# AT32UC3A464S device description
Architecture: AVR32_UC3; Family: AVR UC3
Registers are 32-bit, read-write, reset 0x0 unless marked. A register's access mark holds for its fields unless they carry their own. Offsets are from the block's base; [hi:lo] are bit positions; {n}, {i} and the like mark numbered series.

## AES — Advanced Encryption Standard
Instances: AES 0xfffd0000
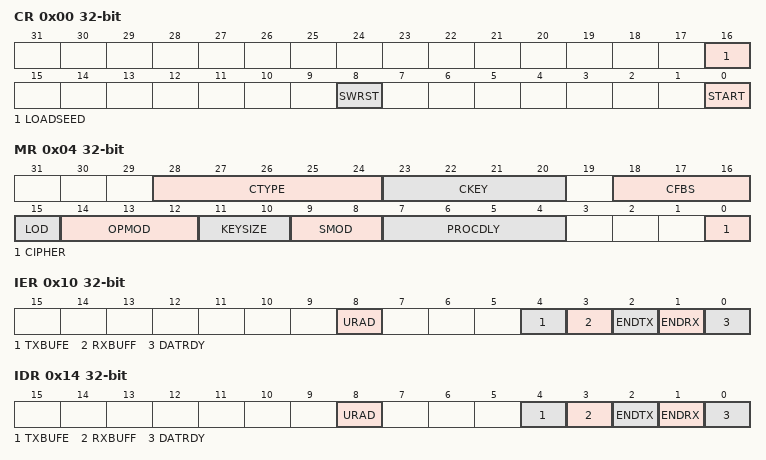
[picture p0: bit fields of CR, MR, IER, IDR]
0x00 CR wo reset not defined — Control Register
  [16] LOADSEED — Random Number Generator Seed Loading
  [8] SWRST — Software Reset
  [0] START — Start Processing
0x04 MR — Mode Register
  [28:24] CTYPE — Countermeasure Type
  [23:20] CKEY — Countermeasure Key
  [18:16] CFBS — Chiper Feedback Data Size
  [15] LOD — Last Output Data Mode
  [14:12] OPMOD — Operation Mode
  [11:10] KEYSIZE
  [9:8] SMOD — Start Mode
  [7:4] PROCDLY — Processing Delay
  [0] CIPHER — Processing Mode
0x10 IER wo reset not defined — Interrupt Enable Register
  [8] URAD — Unspecified Register Access Detection Interrupt Enable
  [4] TXBUFE — Receive Buffer Empty Interrupt Enable
  [3] RXBUFF — Receive Buffer Full Interrupt Enable
  [2] ENDTX — End of Transmit Buffer Interrupt Enable
  [1] ENDRX — End of Receive Buffer Interrupt Enable
  [0] DATRDY — Data Ready Interrupt Enable
0x14 IDR wo reset not defined — Interrupt Disable Register
  [8] URAD — Unspecified Register Access Detection Interrupt Disable
  [4] TXBUFE — Receive Buffer Empty Interrupt Disable
  [3] RXBUFF — Receive Buffer Full Interrupt Disable
  [2] ENDTX — End of Transmit Buffer Interrupt Disable
  [1] ENDRX — End of Receive Buffer Interrupt Disable
  [0] DATRDY — Data Ready Interrupt Disable
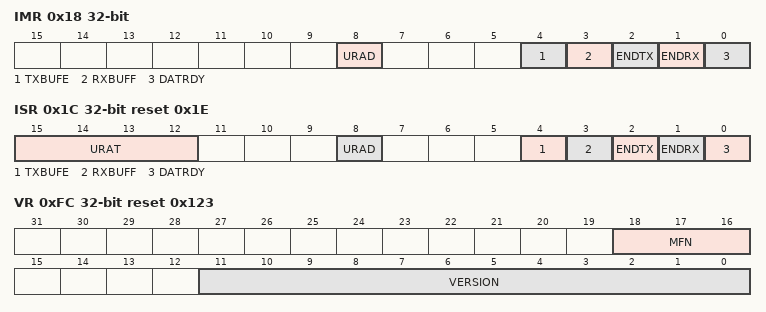
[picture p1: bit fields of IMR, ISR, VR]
0x18 IMR ro — Interrupt Mask Register
  [8] URAD — Unspecified Register Access Detection Interrupt Mask
  [4] TXBUFE — Receive Buffer Empty Interrupt Mask
  [3] RXBUFF — Receive Buffer Full Interrupt Mask
  [2] ENDTX — End of Transmit Buffer Interrupt Mask
  [1] ENDRX — End of Receive Buffer Interrupt Mask
  [0] DATRDY — Data Ready Interrupt Mask
0x1C ISR ro reset 0x1E — Interrupt Status Register
  [15:12] URAT — Unspecified Register Access Type
  [8] URAD — Unspecified Register Access Detection Status
  [4] TXBUFE — TX Buffer Empty
  [3] RXBUFF — RX Buffer Full
  [2] ENDTX — End of TX Buffer
  [1] ENDRX — End of RX Buffer
  [0] DATRDY — Data Ready
{0x1C+4i} KEYW{i}R wo reset not defined (i=1..8) — Key Word {i} Register
  [31:0] KEYWxR — AES Key Word x Register
0x40 IDATA1R wo reset not defined — Input Data 1 Register
  [31:0] IDATAx — Input Data Word x
0x44 IDATA2R wo reset not defined — Input Data 2 Register
  [31:0] IDATAx — Input Data Word x
0x48 IDATA3R wo reset not defined — Input Data 3 Register
  [31:0] IDATAx
0x4C IDATA4R wo reset not defined — Input Data 4 Register
  [31:0] IDATAx
0x50 ODATA1R ro — Output Data 1 Register
  [31:0] ODATAxR — AES Output Data x Register
0x54 ODATA2R ro reset 0xC01F0000 — Output Data 2 Register
  [31:0] ODATAxR — AES Output Data x Register
0x58 ODATA3R ro — Output Data 3 Register
  [31:0] ODATAxR — AES Output Data x Register
0x5C ODATA4R ro — Output Data 4 Register
  [31:0] ODATAxR — AES Output Data x Register
{0x5C+4i} IV{i}R wo reset not defined (i=1..3) — Initialization Vector {i} Register
  [31:0] IVxR — AES Initialization Vector x Register
0x6C IV4E wo reset not defined — Initialization Vector 4 Register
  [31:0] IVxR — AES Initialization Vector x Register
0xFC VR ro reset 0x123 — AES version
  [18:16] MFN — Metal fix number
  [11:0] VERSION — AES version

## BUSMON — Bus Monitor module
Instances: BUSMON 0xfffe2800
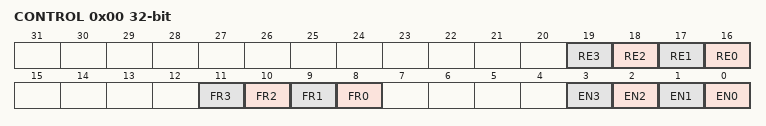
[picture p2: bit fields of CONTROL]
0x00 CONTROL
  [n+16] RE{n} (n=0..3), [n+8] FR{n} (n=0..3), [n] EN{n} (n=0..3)
{0x10+0x10*i} DATA{i} ro (i=0..3) — Data Cycles Channel {i}
{0x14+0x10*i} STALL{i} ro (i=0..3) — Stall Cycles Channel {i}
{0x18+0x10*i} LAT{i} ro (i=0..3) — Max Latency Cycles Channel {i}

## ABDAC — Audio Bitstream DAC
Instances: ABDAC 0xffff4000
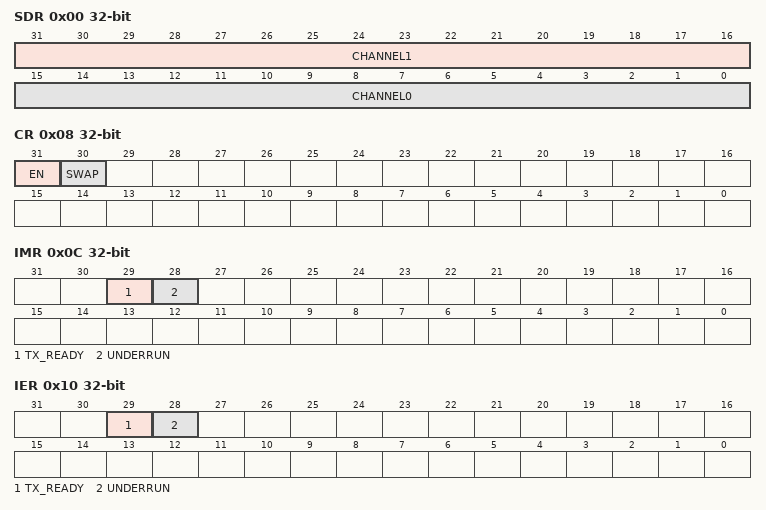
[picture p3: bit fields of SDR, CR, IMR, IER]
0x00 SDR — Sample Data Register
  [31:16] CHANNEL1 — Sample Data for Channel 1
  [15:0] CHANNEL0 — Sample Data for Channel 0
0x08 CR reset not defined — Control Register
  [31] EN — Enable Audio DAC.
  [30] SWAP — Swap Channels
0x0C IMR ro reset not defined — Interrupt Mask Register
  [29] TX_READY — TX Ready Interrupt Mask
  [28] UNDERRUN — Underrun Interrupt Mask
0x10 IER wo reset not defined — Interrupt Enable Register
  [29] TX_READY — TX Ready Interrupt Enable
  [28] UNDERRUN — Underrun Interrupt Enable
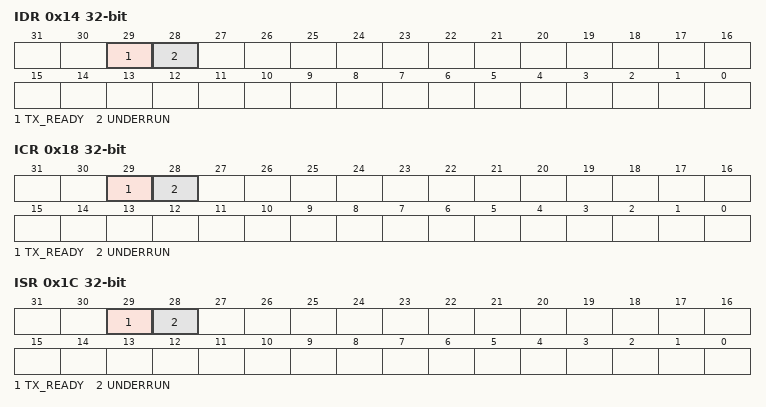
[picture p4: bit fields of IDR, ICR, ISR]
0x14 IDR wo reset not defined — Interupt Disable Register
  [29] TX_READY — TX Ready Interrupt Disable
  [28] UNDERRUN — Underrun Interrupt Disable
0x18 ICR wo reset not defined — Interrupt Clear Register
  [29] TX_READY — TX Ready Interrupt Clear
  [28] UNDERRUN — Underrun Interrupt Clear
0x1C ISR ro reset not defined — Interrupt Status Register
  [29] TX_READY — Interrupt Status Register
  [28] UNDERRUN — Interrupt Status Register
